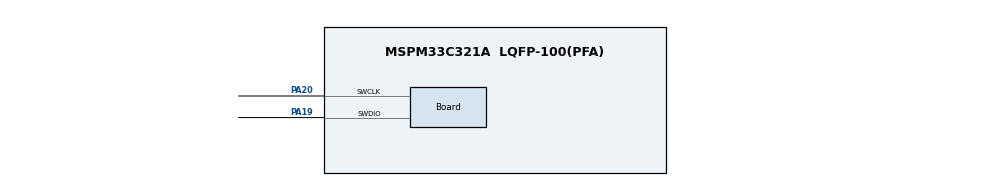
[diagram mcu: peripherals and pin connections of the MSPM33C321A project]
//@cliArgs --device "MSPM33C321A" --package "LQFP-100(PFA)" --part "Default"
//@v2CliArgs --device "MSPM33C321A" --package "LQFP-100(PFA)"
// @cliArgs --board /ti/boards/LP_MSPM33C321A --rtos nortos


/**
 * Import the modules used in this configuration.
 */
const CRCP    = scripting.addModule("/ti/driverlib/CRCP");
const GPIO    = scripting.addModule("/ti/driverlib/GPIO", {}, false);
const GPIO1   = GPIO.addInstance();
const NONMAIN = scripting.addModule("/ti/driverlib/NONMAIN");
const SYSCTL  = scripting.addModule("/ti/driverlib/SYSCTL");

/**
 * Write custom configuration values to the imported modules.
 */
const divider3       = system.clockTree["EXTDIVMCLK"];
divider3.divideValue = 1;

const multiplier2         = system.clockTree["PLL_QDIV"];
multiplier2.multiplyValue = 10;

CRCP.bitReverse = "REVERSED";
CRCP.seed       = 0xFFFFFFFF;

const Board                       = scripting.addModule("/ti/driverlib/Board", {}, false);
Board.peripheral.$assign          = "DEBUGSS";
Board.peripheral.swclkPin.$assign = "PA20";
Board.peripheral.swdioPin.$assign = "PA19";

GPIO1.$name                               = "GPIO_LEDS";
GPIO1.associatedPins.create(2);
GPIO1.associatedPins[0].launchPadShortcut = "LED2GreenEn";
GPIO1.associatedPins[0].$name             = "PASS_LED";
GPIO1.associatedPins[1].$name             = "FAIL_LED";
GPIO1.associatedPins[1].launchPadShortcut = "LED2RedEn";

NONMAIN.nonmainWarning = true;

SYSCTL.forceDefaultClkConfig = true;
SYSCTL.clockTreeEn           = true;

const ProjectConfig              = scripting.addModule("/ti/project_config/ProjectConfig", {}, false);
ProjectConfig.migrationCondition = true;

/**
 * Pinmux solution for unlocked pins/peripherals. This ensures that minor changes to the automatic solver in a future
 * version of the tool will not impact the pinmux you originally saw.  These lines can be completely deleted in order to
 * re-solve from scratch.
 */
GPIO1.associatedPins[0].pin.$suggestSolution = "PC27";
GPIO1.associatedPins[1].pin.$suggestSolution = "PC26";
